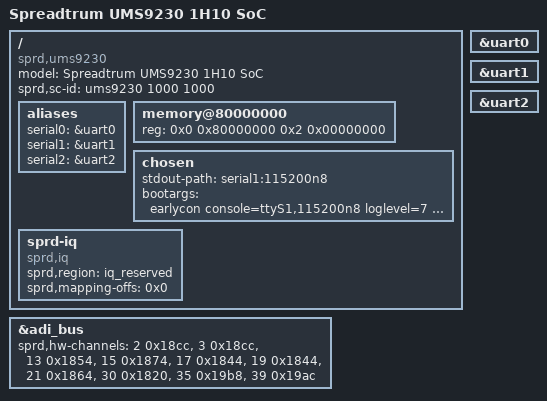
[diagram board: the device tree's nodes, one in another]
// SPDX-License-Identifier: GPL-2.0-only
/*
 * Unisoc Qogirl6 platform DTS file
 *
 * Copyright (C) 2020, Unisoc Inc.
 */

/dts-v1/;

#include <dt-bindings/gpio/gpio.h>
#include "ums9230.dtsi"
#include "sc2730.dtsi"
#include "ums9230-mach.dtsi"
#include "ums9230-modem.dtsi"
#include "lcd/lcd_dummy_mipi.dtsi"

/ {
	model = "Spreadtrum UMS9230 1H10 SoC";

	compatible = "sprd,ums9230";

	sprd,sc-id = "ums9230 1000 1000";

	aliases {
		serial0 = &uart0;
		serial1 = &uart1;
		serial2 = &uart2;
	};

	memory@80000000 {
		device_type = "memory";
		reg = <0x0 0x80000000 0x2 0x00000000>;
	};

	chosen: chosen {
		stdout-path = "serial1:115200n8";
		bootargs = "earlycon console=ttyS1,115200n8 loglevel=7 init=/init root=/dev/ram0 rw printk.devkmsg=on androidboot.boot_devices=soc/soc:ap-apb/201d0000.sdio androidboot.selinux=permissive maxcpus=1";
	};

	sprd-iq {
		compatible = "sprd,iq";
		sprd,region = <&iq_reserved>;
		sprd,mapping-offs = <0x0>;
	};
};

&uart0 {
	status = "okay";
};

&uart1 {
	status = "okay";
};

&uart2 {
	status = "okay";
};

&adi_bus {
	sprd,hw-channels = <2 0x18cc>, <3 0x18cc>, <13 0x1854>, <15 0x1874>,
			 <17 0x1844>,<19 0x1844>, <21 0x1864>, <30 0x1820>,
			 <35 0x19b8>, <39 0x19ac>;
};
